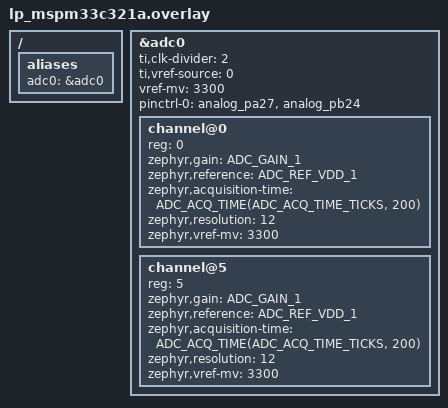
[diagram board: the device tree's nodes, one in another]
/*
 * SPDX-License-Identifier: Apache-2.0
 */

#include <zephyr/dt-bindings/adc/adc.h>

/ {
	aliases {
		adc0 = &adc0;
	};
};

&adc0 {
	ti,clk-divider = <2>;
	ti,vref-source = <0>;  /* VDDA (3.3V) */
	vref-mv = <3300>;
	pinctrl-0 = <&analog_pa27 &analog_pb24>;
	pinctrl-names = "default";
	#address-cells = <1>;
	#size-cells = <0>;

	channel@0 {
		reg = <0>;
		zephyr,gain = "ADC_GAIN_1";
		zephyr,reference = "ADC_REF_VDD_1";
		zephyr,acquisition-time = <ADC_ACQ_TIME(ADC_ACQ_TIME_TICKS, 200)>;
		zephyr,resolution = <12>;
		zephyr,vref-mv = <3300>;
	};

	channel@5 {
		reg = <5>;
		zephyr,gain = "ADC_GAIN_1";
		zephyr,reference = "ADC_REF_VDD_1";
		zephyr,acquisition-time = <ADC_ACQ_TIME(ADC_ACQ_TIME_TICKS, 200)>;
		zephyr,resolution = <12>;
		zephyr,vref-mv = <3300>;
	};
};
